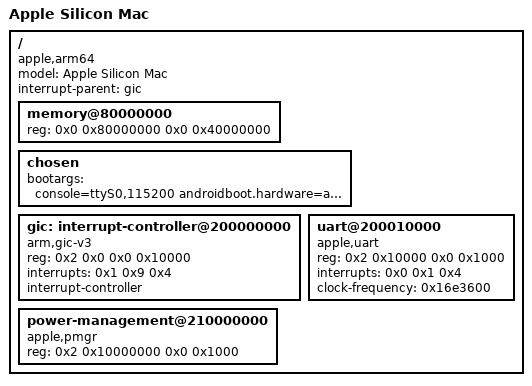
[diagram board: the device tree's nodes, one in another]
/dts-v1/;

/ {
    compatible = "apple,arm64";
    model = "Apple Silicon Mac";
    #address-cells = <2>;
    #size-cells = <2>;

    interrupt-parent = <&gic>;

    memory@80000000 {
        device_type = "memory";
        reg = <0x0 0x80000000 0x0 0x40000000>; // 1GB RAM
    };

    chosen {
        bootargs = "console=ttyS0,115200 androidboot.hardware=apple androidboot.mode=normal";
    };

    gic: interrupt-controller@200000000 {
        compatible = "arm,gic-v3";
        reg = <0x2 0x0 0x0 0x10000>;
        interrupts = <0x1 0x9 0x4>;
        interrupt-controller;
        #interrupt-cells = <3>;
    };

    uart@200010000 {
        compatible = "apple,uart";
        reg = <0x2 0x10000 0x0 0x1000>;
        interrupts = <0x0 0x1 0x4>;
        clock-frequency = <0x16e3600>;
    };

    power-management@210000000 {
        compatible = "apple,pmgr";
        reg = <0x2 0x10000000 0x0 0x1000>;
    };
};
